# STM32G081 register map
File version: 1.8
CPU: CM0 r0p1, little endian, MPU, no FPU, 2 interrupt priority bits
Registers are 32-bit, read-write, reset 0x0 unless marked. A register's access mark holds for its fields unless they carry their own. Offsets are from the block's base; [hi:lo] are bit positions; {n}, {i} and the like mark numbered series.

## IWDG — Independent watchdog
Base 0x40003000
0x00 KR 16-bit wo — Key register
  [15:0] KEY — Key value (write only, read 0x0000)
    0x5555=Unlock (Enable access to PR, RLR and WINR registers); 0xAAAA=Feed watchdog with RLR register value; 0xCCCC=Start the watchdog
0x04 PR 16-bit — Prescaler register
  [2:0] PR — Prescaler divider
    0=DivideBy4 (Divider /4); 1=DivideBy8 (Divider /8); 2=DivideBy16 (Divider /16); 3=DivideBy32 (Divider /32); 4=DivideBy64 (Divider /64); 5=DivideBy128 (Divider /128); other=DivideBy256 (Divider /256)
0x08 RLR 16-bit reset 0xFFF — Reload register
  [11:0] RL — Watchdog counter reload value
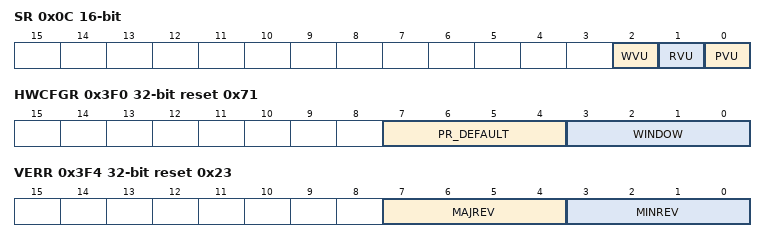
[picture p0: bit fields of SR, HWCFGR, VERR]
0x0C SR 16-bit ro — Status register
  [2] WVU — Watchdog counter window value update
  [1] RVU — Watchdog counter reload value update
  [0] PVU — Watchdog prescaler value update
0x10 WINR 16-bit reset 0xFFF — Window register
  [11:0] WIN — Watchdog counter window value
0x3F0 HWCFGR reset 0x71 — hardware configuration register
  [7:4] PR_DEFAULT — Prescaler default value
  [3:0] WINDOW — Support of Window function
0x3F4 VERR ro reset 0x23 — EXTI IP Version register
  [7:4] MAJREV — Major Revision number
  [3:0] MINREV — Minor Revision number
0x3F8 IPIDR ro reset 0x120041 — EXTI Identification register
  [31:0] IPID — IP Identification
0x3FC SIDR ro reset 0xA3C5DD01 — EXTI Size ID register
  [31:0] SID — Size Identification

## WWDG — System window watchdog
Base 0x40002C00
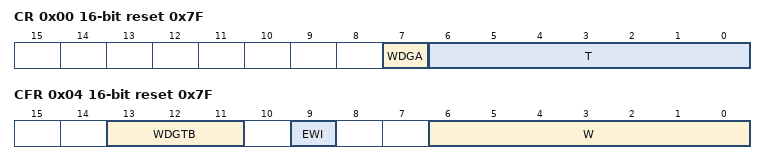
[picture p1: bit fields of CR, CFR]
0x00 CR 16-bit reset 0x7F — Control register
  [7] WDGA — Activation bit
    0=Disabled (Watchdog disabled); 1=Enabled (Watchdog enabled)
  [6:0] T — 7-bit counter (MSB to LSB)
0x04 CFR 16-bit reset 0x7F — Configuration register
  [13:11] WDGTB — Timer base
    0=Div1 (Counter clock (PCLK1 div 4096) div 1); 1=Div2 (Counter clock (PCLK1 div 4096) div 2); 2=Div4 (Counter clock (PCLK1 div 4096) div 4); 3=Div8 (Counter clock (PCLK1 div 4096) div 8); 4=Div16 (Counter clock (PCLK1 div 4096) div 16); 5=Div32 (Counter clock (PCLK1 div 4096) div 32); 6=Div64 (Counter clock (PCLK1 div 4096) div 64); 7=Div128 (Counter clock (PCLK1 div 4096) div 128)
  [9] EWI — Early wakeup interrupt
    on write: 1=Enable (interrupt occurs whenever the counter reaches the value 0x40)
  [6:0] W — 7-bit window value
0x08 SR 16-bit — Status register
  [0] EWIF write-0-clears — Early wakeup interrupt flag
    on read: 0=Finished (The EWI Interrupt Service Routine has been serviced); 1=Pending (The EWI Interrupt Service Routine has been triggered) | on write: 0=Finished (The EWI Interrupt Service Routine has been serviced)

## DBG — Debug support
Base 0x40015800
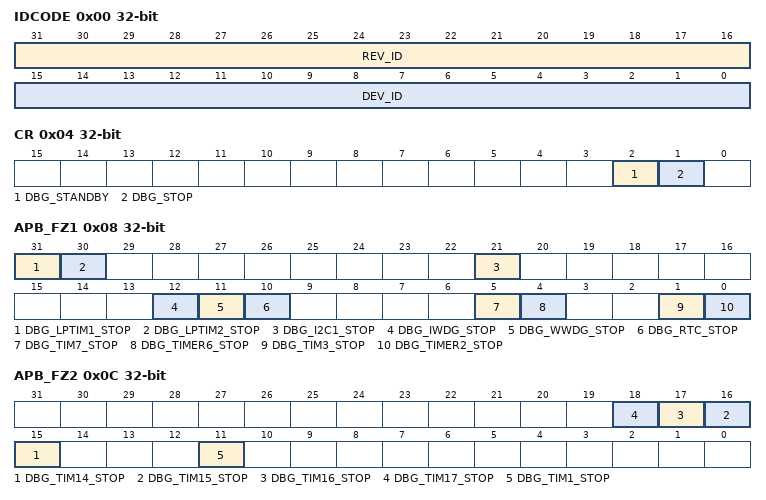
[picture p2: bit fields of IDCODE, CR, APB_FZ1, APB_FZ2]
0x00 IDCODE ro — MCU Device ID Code Register
  [31:16] REV_ID — Revision Identifier
  [15:0] DEV_ID — Device Identifier
0x04 CR — Debug MCU Configuration Register
  [2] DBG_STANDBY — Debug Standby Mode
  [1] DBG_STOP — Debug Stop Mode
0x08 APB_FZ1 — DBG APB freeze register 1
  [31] DBG_LPTIM1_STOP — Clocking of LPTIMER1 counter when the core is halted
  [30] DBG_LPTIM2_STOP — Clocking of LPTIMER2 counter when the core is halted
  [21] DBG_I2C1_STOP — I2C1 SMBUS timeout mode stopped when core is halted
  [12] DBG_IWDG_STOP — Debug Independent Wachdog stopped when Core is halted
  [11] DBG_WWDG_STOP — Debug Window Wachdog stopped when Core is halted
  [10] DBG_RTC_STOP — Debug RTC stopped when Core is halted
  [5] DBG_TIM7_STOP — TIM7 counter stopped when core is halted
  [4] DBG_TIMER6_STOP — Debug Timer 6 stopped when Core is halted
  [1] DBG_TIM3_STOP — TIM3 counter stopped when core is halted
  [0] DBG_TIMER2_STOP — Debug Timer 2 stopped when Core is halted
0x0C APB_FZ2 — DBG APB freeze register 2
  [n+1] DBG_TIM{n}_STOP (n=14..17), [11] DBG_TIM1_STOP
